# nrf9220_application register map
Vendor: Nordic Semiconductor; Series: nRF92; File version: 1
CPU: CM33 r1p0, little endian, MPU, FPU, 3 interrupt priority bits, 480 interrupts, 4 SAU regions
Registers are 32-bit, read-write, reset 0x0 unless marked. A register's access mark holds for its fields unless they carry their own. Offsets are from the block's base; [hi:lo] are bit positions; lines under a group give offsets from that group; {n}, {i} and the like mark numbered series; 'fields as' and 'values as' point back to an identical list.

## GLOBAL_BELLBOARD_SEC_NS — BELLBOARD public registers 0
Base 0x5F099000
Same registers: GLOBAL_BELLBOARD_SEC_S 0x5F099000 (alternate view of GLOBAL_BELLBOARD_SEC_NS), GLOBAL_BELLBOARD_APP_NS 0x5F09A000 (alternate view of BELLBOARD_S), GLOBAL_BELLBOARD_APP_S 0x5F09A000 (alternate view of BELLBOARD_S), GLOBAL_BELLBOARD_CELLCORE_NS 0x5F09C000, GLOBAL_BELLBOARD_CELLCORE_S 0x5F09C000 (alternate view of GLOBAL_BELLBOARD_CELLCORE_NS)
{0x0+4i} TASKS_TRIGGER[{i}] (i=0..31) wo — Description collection: Task TRIGGER[n]
  [0] TASKS_TRIGGER — Task TRIGGER[n]
    1=Trigger task

## GLOBAL_MUTEX120_NS — MUTEX 0
Base 0x4F8D2000
Same registers: GLOBAL_MUTEX130_NS 0x4F927000
{0x400+4i} MUTEX[{i}] (i=0..31) — Description collection: Mutex register
  [0] MUTEX — Mutex register n
    0=Unlocked (Mutex n is in unlocked state); 1=Locked (Mutex n is in locked state)

## GLOBAL_DPPIC120_NS — Distributed programmable peripheral interconnect controller 0
Base 0x4F8E1000
Same registers: GLOBAL_DPPIC130_NS 0x4F922000, GLOBAL_DPPIC131_NS 0x4F981000, GLOBAL_DPPIC132_NS 0x4F991000, GLOBAL_DPPIC133_NS 0x4F9A1000, GLOBAL_DPPIC134_NS 0x4F9B1000, GLOBAL_DPPIC120_S 0x5F8E1000, GLOBAL_DPPIC130_S 0x5F922000, GLOBAL_DPPIC131_S 0x5F981000, GLOBAL_DPPIC132_S 0x5F991000, GLOBAL_DPPIC133_S 0x5F9A1000, GLOBAL_DPPIC134_S 0x5F9B1000
{0x0+8i} TASKS_CHG[{i}] (i=0..3) group — Channel group tasks
  0x00 EN wo — Description cluster: Enable channel group n
    [0] EN — Enable channel group n
      1=Trigger task
  0x04 DIS wo — Description cluster: Disable channel group n
    [0] DIS — Disable channel group n
      1=Trigger task
{0x80+8i} SUBSCRIBE_CHG[{i}] (i=0..3) group — Subscribe configuration for tasks
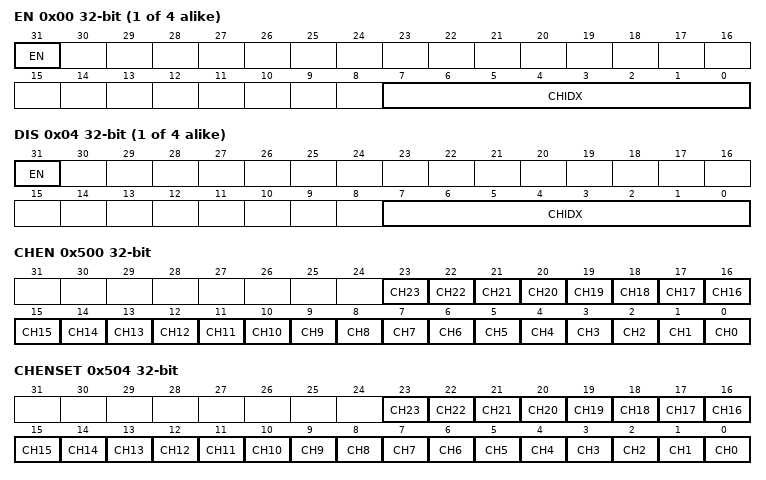
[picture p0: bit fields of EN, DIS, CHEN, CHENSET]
  0x00 EN — Description cluster: Subscribe configuration for task CHG[n].EN
    [31] EN
      0=Disabled (Disable subscription); 1=Enabled (Enable subscription)
    [7:0] CHIDX — DPPI channel that task CHG[n].EN will subscribe to
  0x04 DIS — Description cluster: Subscribe configuration for task CHG[n].DIS
    [31] EN
      values as SUBSCRIBE_CHG[0].EN.EN
    [7:0] CHIDX — DPPI channel that task CHG[n].DIS will subscribe to
0x500 CHEN — Channel enable register
  [all] fields
    0=Disabled (Disable channel); 1=Enabled (Enable channel)
  [n] CH{n} (n=0..23) — Enable or disable channel {n}
0x504 CHENSET write-1-sets — Channel enable set register
  [all] fields
    on read: 0=Disabled (Read: Channel disabled); 1=Enabled (Read: Channel enabled) | on write: 1=Set (Write: Enable channel)
  [n] CH{n} (n=0..23) — Channel {n} enable set register. Writing 0 has no effect.
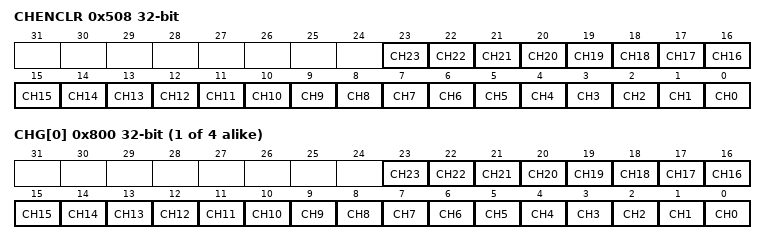
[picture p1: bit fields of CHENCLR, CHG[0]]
0x508 CHENCLR write-1-clears — Channel enable clear register
  [all] fields
    on read: 0=Disabled (Read: Channel disabled); 1=Enabled (Read: Channel enabled) | on write: 1=Clear (Write: Disable channel)
  [n] CH{n} (n=0..23) — Channel {n} enable clear register. Writing 0 has no effect.
{0x800+4i} CHG[{i}] (i=0..3) — Description collection: Channel group n Note: Writes to this register are ignored if either SUBSCRIBE_CHG[n].EN or SUBSCRIBE_CHG[n].DIS is enabled
  [all] fields
    0=Excluded; 1=Included
  [n] CH{n} (n=0..23) — Include or exclude channel {n}

## GLOBAL_AHBBUFFER130_NS — AHB Buffer 0
Base 0x4F90A000
Same registers: GLOBAL_AHBBUFFER130_S 0x5F90A000
0x100 EVENTS_BUSERROR — Error response to posted write
  [0] EVENTS_BUSERROR
    0=NotGenerated (Event not generated); 1=Generated (Event generated)
0x200 SHORTS — Shortcuts between local events and tasks
0x300 INTEN — Enable or disable interrupt
  [0] BUSERROR — Enable or disable interrupt for event BUSERROR
    0=Disabled; 1=Enabled
0x304 INTENSET — Enable interrupt
  [0] BUSERROR write-1-sets — Write '1' to enable interrupt for event BUSERROR
    on read: 0=Disabled (Read: Disabled); 1=Enabled (Read: Enabled) | on write: 1=Set (Enable)
0x308 INTENCLR — Disable interrupt
  [0] BUSERROR write-1-clears — Write '1' to disable interrupt for event BUSERROR
    on read: 0=Disabled (Read: Disabled); 1=Enabled (Read: Enabled) | on write: 1=Clear (Disable)
0x30C INTPEND ro — Pending interrupts
  [0] BUSERROR — Read pending status of interrupt for event BUSERROR
    on read: 0=NotPending (Read: Not pending); 1=Pending (Read: Pending)
0x500 OPMODE — Operation mode
  [1:0] OPMODE
    0=f0 (Bypass); 1=f1 (Post all writes); 2=f2 (Obey hposted input); 3=f3 (Take OpMode from port)
0x504 ERRORADDRENABLE — Enable bit for error address tracking
  [0] ERRORADDRENABLE — Tracking must be enabled when it is needed. Detected error response for posted write (EVENT BUSERROR) will halt tracking and change the value of this register to 0.
    0=e0 (Error address is not tracked); 1=e1 (Error address is tracked)
0x508 ERRORADDR — Address for posted write error response
  [31:0] ERRORADDR — First address that caused error response for posted write. Valid only when EVENT BUSERROR is 1.
